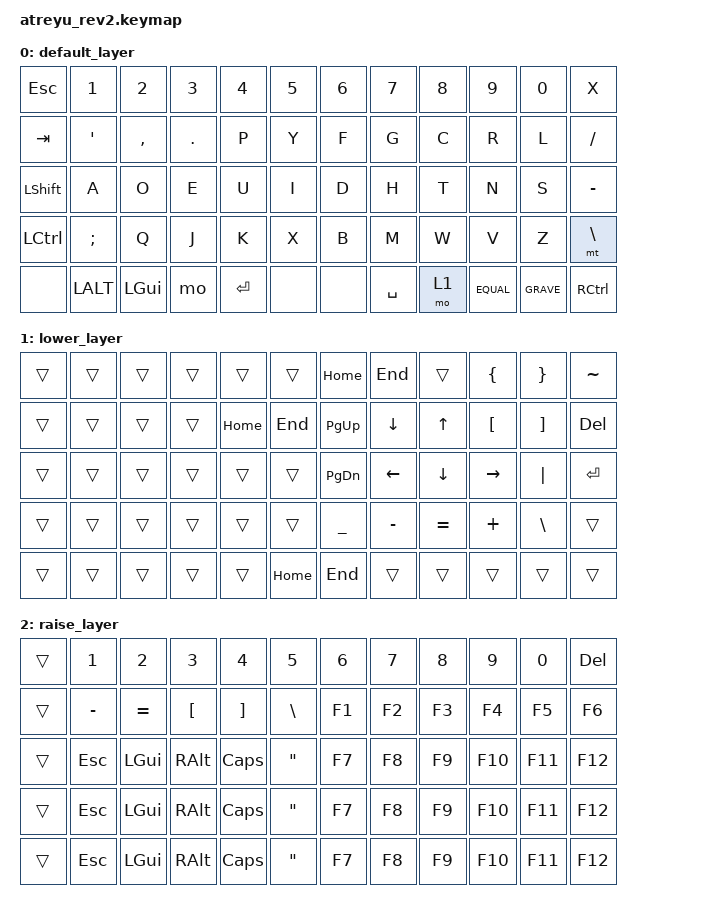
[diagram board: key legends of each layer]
/*
 * Copyright (c) 2020 The ZMK Contributors
 *
 * SPDX-License-Identifier: MIT
 */

#include <behaviors.dtsi>
#include <dt-bindings/zmk/keys.h>
#include <dt-bindings/zmk/bt.h>
// #include <dt-bindings/zmk/rgb.h>

/ {
        keymap {
                compatible = "zmk,keymap";

                default_layer {
                        bindings = <
   &kp ESC   &kp N1   &kp N2   &kp N3   &kp N4  &kp N5    &kp N6 &kp N7    &kp N8    &kp N9  &kp N0   &kp X
   &kp TAB   &kp SQT  &kp COMMA &kp DOT  &kp P   &kp Y     &kp F  &kp G   &kp C     &kp R   &kp L    &kp SLASH
   &kp LSHFT &kp A    &kp O    &kp E    &kp U   &kp I     &kp D  &kp H     &kp T     &kp N   &kp S    &kp MINUS
   &kp LCTRL &kp SEMI &kp Q   &kp J    &kp K   &kp X     &kp B  &kp M     &kp W     &kp V   &kp Z    &mt BSLH
   &none     &LALT   &kp LGUI &kp mo 2   &kp RET &none     &none  &kp SPACE &mo 1     &EQUAL  &GRAVE   &kp RCTRL
                        >;
			sensor-bindings = <&inc_dec_kp C_VOL_UP C_VOL_DN>;
                };

                lower_layer {
                        bindings = <
   &trans &trans &trans &trans &trans   &trans        &kp HOME  &kp END   &trans    &kp LBRC   &kp RBRC  &kp TILDE
   &trans &trans &trans &trans &kp HOME &kp END       &kp PG_UP &kp DOWN  &kp UP    &kp LBKT   &kp RBKT  &kp DEL
   &trans &trans &trans &trans &trans   &trans        &kp PG_DN &kp LEFT  &kp DOWN  &kp RIGHT  &kp PIPE  &kp RET
   &trans &trans &trans &trans &trans   &trans        &kp UNDER &kp MINUS &kp EQUAL &kp PLUS   &kp BSLH  &trans
   &trans &trans &trans &trans &trans   &kp HOME      &kp END   &trans    &trans    &trans     &trans    &trans
                        >;
			sensor-bindings = <&inc_dec_kp C_VOL_UP C_VOL_DN>;
                };

                raise_layer {
// -----------------------------------------------------------------------------------------
// |    |  1  |  2  |  3  |  4  |  5  |   |  6  |  7  |  8  |  9  |  0  | DEL |
// |    |  -  |  =  |  [  |  ]  |  \  |   | F1  | F2  | F3  | F4  | F5  | F6  |
// |    | ESC | GUI | ALT | CAPS|  "  |   | F7  | F8  | F9  | F10 | F11 | F12 |
//                       |     | ADJ | BKSP |    |     |
                        bindings = <
   &trans &kp N1    &kp N2    &kp N3    &kp N4    &kp N5        &kp N6    &kp N7    &kp N8    &kp N9    &kp N0    &kp DEL
   &trans &kp MINUS &kp EQUAL &kp LBKT  &kp RBKT  &kp BSLH      &kp F1    &kp F2    &kp F3    &kp F4    &kp F5    &kp F6
   &trans &kp ESC   &kp LGUI  &kp RALT  &kp CLCK  &kp DQT       &kp F7    &kp F8    &kp F9    &kp F10   &kp F11   &kp F12
   &trans &kp ESC   &kp LGUI  &kp RALT  &kp CLCK  &kp DQT       &kp F7    &kp F8    &kp F9    &kp F10   &kp F11   &kp F12
   &trans &kp ESC   &kp LGUI  &kp RALT  &kp CLCK  &kp DQT       &kp F7    &kp F8    &kp F9    &kp F10   &kp F11   &kp F12
//                                &trans      &mo 3       &kp BSPC        &trans      &trans
                        >;
			sensor-bindings = <&inc_dec_kp C_VOL_UP C_VOL_DN>;
                };
//                adjust_layer {
// -----------------------------------------------------------------------------------------
// | RGB BRI+ | RGB SAT+ | RGB HUE+ | RGB ANI+ |    | RGB TOG |   |  BT1  | BT2 | BT3 | BT4 | BT5 | BT CLR |
// | RGB BRI- | RGB SAT- | RGB HUE- | RGB ANI- |    |         |   |       |     |     |     |     |        |
// |          |          |          |          |    |         |   | RESET |     |     |     |     |        |
//                                              |     |     |     |     |     |
//                        bindings = <
//   &rgb_ug RGB_BRI &rgb_ug RGB_SAI &rgb_ug RGB_HUI &rgb_ug RGB_EFF &none &rgb_ug RGB_TOG    &bt BT_SEL 0 &bt BT_SEL 1 &bt BT_SEL 2 &bt BT_SEL 3 &bt BT_SEL 4 &bt BT_CLR
//   &rgb_ug RGB_BRD &rgb_ug RGB_SAD &rgb_ug RGB_HUD &rgb_ug RGB_EFR &none &none              &none        &none        &none        &none        &none        &none
//   &none           &none           &none           &none           &none &none              &reset       &none        &none        &none        &none        &none
//                                                             &trans      &trans       &tog 3        &trans      &trans
//                        >;
//               };
        };
};
